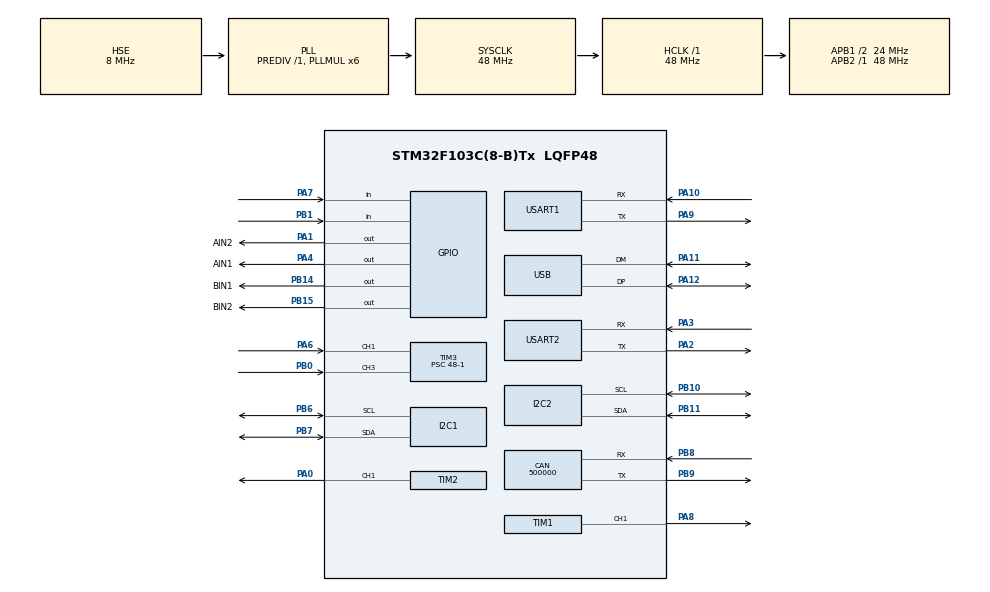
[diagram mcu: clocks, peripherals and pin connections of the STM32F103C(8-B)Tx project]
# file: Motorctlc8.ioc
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CAN.CalculateBaudRate=500000
CAN.CalculateTimeBit=2000
CAN.CalculateTimeQuantum=666.6666666666666
FREERTOS.Tasks01=IMUTask,0,128,IMUFunc,Default,NULL,Dynamic,NULL,NULL;DataTask,0,128,DataFunc,Default,NULL,Dynamic,NULL,NULL;BlanceTask,0,128,BlanceFunc,Default,NULL,Dynamic,NULL,NULL
Mcu.Family=STM32F1
Mcu.Name=STM32F103C(8-B)Tx
Mcu.Package=LQFP48
NVIC.PriorityGroup=NVIC_PRIORITYGROUP_4
NVIC.TIM3_IRQn=true\:5\:0\:false\:false\:true\:true\:true\:true\:true
NVIC.TIM4_IRQn=true\:15\:0\:false\:false\:true\:false\:false\:true\:true
NVIC.TimeBase=TIM4_IRQn
NVIC.TimeBaseIP=TIM4
NVIC.USB_LP_CAN1_RX0_IRQn=true\:5\:0\:false\:false\:true\:true\:false\:true\:true
PA0-WKUP.Signal=S_TIM2_CH1_ETR
PA1.GPIO_Label=AIN2
PA1.Signal=GPIO_Output
PA10.Mode=Asynchronous
PA10.Signal=USART1_RX
PA11.Mode=Device
PA11.Signal=USB_DM
PA12.Mode=Device
PA12.Signal=USB_DP
PA13.Mode=Serial_Wire
PA13.Signal=SYS_JTMS-SWDIO
PA14.Mode=Serial_Wire
PA14.Signal=SYS_JTCK-SWCLK
PA2.Mode=Asynchronous
PA2.Signal=USART2_TX
PA3.Mode=Asynchronous
PA3.Signal=USART2_RX
PA4.GPIO_Label=AIN1
PA4.Signal=GPIO_Output
PA6.Signal=S_TIM3_CH1
PA7.Signal=GPIO_Input
PA8.Signal=S_TIM1_CH1
PA9.Mode=Asynchronous
PA9.Signal=USART1_TX
PB0.Signal=S_TIM3_CH3
PB1.Signal=GPIO_Input
PB10.Mode=I2C
PB10.Signal=I2C2_SCL
PB11.Mode=I2C
PB11.Signal=I2C2_SDA
PB14.GPIO_Label=BIN1
PB14.Signal=GPIO_Output
PB15.GPIO_Label=BIN2
PB15.Signal=GPIO_Output
PB6.Mode=I2C
PB6.Signal=I2C1_SCL
PB7.Mode=I2C
PB7.Signal=I2C1_SDA
PB8.Mode=CAN_Activate
PB8.Signal=CAN_RX
PB9.Mode=CAN_Activate
PB9.Signal=CAN_TX
PD0-OSC_IN.Mode=HSE-External-Oscillator
PD0-OSC_IN.Signal=RCC_OSC_IN
PD1-OSC_OUT.Mode=HSE-External-Oscillator
PD1-OSC_OUT.Signal=RCC_OSC_OUT
ProjectManager.HeapSize=0x200
ProjectManager.StackSize=0x400
ProjectManager.TargetToolchain=STM32CubeIDE
RCC.AHBFreq_Value=48000000
RCC.APB1CLKDivider=RCC_HCLK_DIV2
RCC.APB1Freq_Value=24000000
RCC.APB1TimFreq_Value=48000000
RCC.APB2Freq_Value=48000000
RCC.APB2TimFreq_Value=48000000
RCC.HCLKFreq_Value=48000000
RCC.PLLMUL=RCC_PLL_MUL6
RCC.SYSCLKFreq_VALUE=48000000
RCC.SYSCLKSource=RCC_SYSCLKSOURCE_PLLCLK
RCC.USBFreq_Value=48000000
SH.S_TIM1_CH1.0=TIM1_CH1,PWM Generation1 CH1
SH.S_TIM2_CH1_ETR.0=TIM2_CH1,PWM Generation1 CH1
SH.S_TIM3_CH1.0=TIM3_CH1,Input_Capture1_from_TI1
SH.S_TIM3_CH3.0=TIM3_CH3,Input_Capture3_from_TI3
TIM1.Channel-PWM\ Generation1\ CH1=TIM_CHANNEL_1
TIM1.Period=2000
TIM1.Prescaler=48-1
TIM2.Channel-PWM\ Generation1\ CH1=TIM_CHANNEL_1
TIM2.Period=2000
TIM2.Prescaler=48-1
TIM3.AutoReloadPreload=TIM_AUTORELOAD_PRELOAD_ENABLE
TIM3.Channel-Input_Capture1_from_TI1=TIM_CHANNEL_1
TIM3.Channel-Input_Capture3_from_TI3=TIM_CHANNEL_3
TIM3.ClockDivision=TIM_CLOCKDIVISION_DIV2
TIM3.ICFilter_CH1=1
TIM3.ICFilter_CH3=1
TIM3.ICPolarity_CH1=TIM_INPUTCHANNELPOLARITY_FALLING
TIM3.ICPolarity_CH3=TIM_INPUTCHANNELPOLARITY_FALLING
TIM3.ICPrescaler-Input_Capture1_from_TI1=TIM_ICPSC_DIV2
TIM3.ICPrescaler-Input_Capture3_from_TI3=TIM_ICPSC_DIV2
TIM3.Period=50000-1
TIM3.Prescaler=48-1
USART1.VirtualMode=VM_ASYNC
USART2.VirtualMode=VM_ASYNC
USB_DEVICE.CLASS_NAME_FS=HID
USB_DEVICE.VirtualMode=Hid
USB_DEVICE.VirtualModeFS=Hid_FS
VP_FREERTOS_VS_CMSIS_V1.Mode=CMSIS_V1
VP_SYS_VS_tim4.Mode=TIM4
VP_TIM1_VS_ClockSourceINT.Mode=Internal
VP_TIM2_VS_ClockSourceINT.Mode=Internal
VP_TIM3_VS_ClockSourceINT.Mode=Internal
VP_TIM3_VS_ClockSourceITR.Mode=TriggerSource_ITR0
VP_TIM3_VS_ControllerModeTrigger.Mode=Trigger Mode
VP_USB_DEVICE_VS_USB_DEVICE_HID_FS.Mode=HID_FS
board=custom

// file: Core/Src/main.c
/* USER CODE BEGIN Header */
/**
  ******************************************************************************
  * @file           : main.c
  * @brief          : Main program body
  ******************************************************************************
  * @attention
  *
  * Copyright (c) 2025 STMicroelectronics.
  * All rights reserved.
  *
  * This software is licensed under terms that can be found in the LICENSE file
  * in the root directory of this software component.
  * If no LICENSE file comes with this software, it is provided AS-IS.
  *
  ******************************************************************************
  */
/* USER CODE END Header */
#include "main.h"
#include "cmsis_os.h"
#include "can.h"
#include "i2c.h"
#include "tim.h"
#include "usart.h"
#include "usb_device.h"
#include "gpio.h"

/* USER CODE BEGIN Includes */
#include "motor_gm37hallencoder.h"
/* USER CODE END Includes */

void SystemClock_Config(void);
void MX_FREERTOS_Init(void);

int main(void)
{

  /* MCU Configuration--------------------------------------------------------*/

  /* Reset of all peripherals, Initializes the Flash interface and the Systick. */
  HAL_Init();

  /* Configure the system clock */
  SystemClock_Config();

  /* Initialize all configured peripherals */
  MX_GPIO_Init();
  MX_CAN_Init();
  MX_I2C1_Init();
  MX_I2C2_Init();
  MX_TIM1_Init();
  MX_TIM2_Init();
  MX_USART1_UART_Init();
  MX_USART2_UART_Init();
  MX_TIM3_Init();
  /* USER CODE BEGIN 2 */
  App_Init();
  /* USER CODE END 2 */

  /* Call init function for freertos objects (in cmsis_os2.c) */
  MX_FREERTOS_Init();

  /* Start scheduler */
  osKernelStart();

  /* We should never get here as control is now taken by the scheduler */

  /* Infinite loop */
  while (1)
  {

  }
}

void SystemClock_Config(void)
{
  RCC_OscInitTypeDef RCC_OscInitStruct = {0};
  RCC_ClkInitTypeDef RCC_ClkInitStruct = {0};
  RCC_PeriphCLKInitTypeDef PeriphClkInit = {0};

  /** Initializes the RCC Oscillators according to the specified parameters
  * in the RCC_OscInitTypeDef structure.
  */
  RCC_OscInitStruct.OscillatorType = RCC_OSCILLATORTYPE_HSE;
  RCC_OscInitStruct.HSEState = RCC_HSE_ON;
  RCC_OscInitStruct.HSEPredivValue = RCC_HSE_PREDIV_DIV1;
  RCC_OscInitStruct.HSIState = RCC_HSI_ON;
  RCC_OscInitStruct.PLL.PLLState = RCC_PLL_ON;
  RCC_OscInitStruct.PLL.PLLSource = RCC_PLLSOURCE_HSE;
  RCC_OscInitStruct.PLL.PLLMUL = RCC_PLL_MUL6;
  if (HAL_RCC_OscConfig(&RCC_OscInitStruct) != HAL_OK)
  {
    Error_Handler();
  }

  /** Initializes the CPU, AHB and APB buses clocks
  */
  RCC_ClkInitStruct.ClockType = RCC_CLOCKTYPE_HCLK|RCC_CLOCKTYPE_SYSCLK
                              |RCC_CLOCKTYPE_PCLK1|RCC_CLOCKTYPE_PCLK2;
  RCC_ClkInitStruct.SYSCLKSource = RCC_SYSCLKSOURCE_PLLCLK;
  RCC_ClkInitStruct.AHBCLKDivider = RCC_SYSCLK_DIV1;
  RCC_ClkInitStruct.APB1CLKDivider = RCC_HCLK_DIV2;
  RCC_ClkInitStruct.APB2CLKDivider = RCC_HCLK_DIV1;

  if (HAL_RCC_ClockConfig(&RCC_ClkInitStruct, FLASH_LATENCY_1) != HAL_OK)
  {
    Error_Handler();
  }
  PeriphClkInit.PeriphClockSelection = RCC_PERIPHCLK_USB;
  PeriphClkInit.UsbClockSelection = RCC_USBCLKSOURCE_PLL;
  if (HAL_RCCEx_PeriphCLKConfig(&PeriphClkInit) != HAL_OK)
  {
    Error_Handler();
  }
}

void HAL_TIM_PeriodElapsedCallback(TIM_HandleTypeDef *htim)
{
  if (htim->Instance == TIM4)
  {
    HAL_IncTick();
  }
  /* USER CODE BEGIN Callback 1 */
  MotorGM37_PeriodElapsedCallback(htim);
  /* USER CODE END Callback 1 */
}

void Error_Handler(void)
{
  __disable_irq();
  while (1)
  {
  }
}

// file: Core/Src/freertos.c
/* USER CODE BEGIN Header */
/**
  ******************************************************************************
  * File Name          : freertos.c
  * Description        : Code for freertos applications
  ******************************************************************************
  * @attention
  *
  * Copyright (c) 2025 STMicroelectronics.
  * All rights reserved.
  *
  * This software is licensed under terms that can be found in the LICENSE file
  * in the root directory of this software component.
  * If no LICENSE file comes with this software, it is provided AS-IS.
  *
  ******************************************************************************
  */
/* USER CODE END Header */

#include "FreeRTOS.h"
#include "task.h"
#include "main.h"
#include "cmsis_os.h"

osThreadId IMUTaskHandle;
osThreadId DataTaskHandle;
osThreadId BlanceTaskHandle;

void IMUFunc(void const * argument);
void DataFunc(void const * argument);
void BlanceFunc(void const * argument);

extern void MX_USB_DEVICE_Init(void);
void MX_FREERTOS_Init(void); /* (MISRA C 2004 rule 8.1) */

/* GetIdleTaskMemory prototype (linked to static allocation support) */
void vApplicationGetIdleTaskMemory( StaticTask_t **ppxIdleTaskTCBBuffer, StackType_t **ppxIdleTaskStackBuffer, uint32_t *pulIdleTaskStackSize );

/* USER CODE BEGIN GET_IDLE_TASK_MEMORY */
static StaticTask_t xIdleTaskTCBBuffer;
static StackType_t xIdleStack[configMINIMAL_STACK_SIZE];

void vApplicationGetIdleTaskMemory( StaticTask_t **ppxIdleTaskTCBBuffer, StackType_t **ppxIdleTaskStackBuffer, uint32_t *pulIdleTaskStackSize )
{
  *ppxIdleTaskTCBBuffer = &xIdleTaskTCBBuffer;
  *ppxIdleTaskStackBuffer = &xIdleStack[0];
  *pulIdleTaskStackSize = configMINIMAL_STACK_SIZE;
  /* place for user code */
}
/* USER CODE END GET_IDLE_TASK_MEMORY */

void MX_FREERTOS_Init(void) {

  /* Create the thread(s) */
  /* definition and creation of IMUTask */
  osThreadDef(IMUTask, IMUFunc, osPriorityNormal, 0, 128);
  IMUTaskHandle = osThreadCreate(osThread(IMUTask), NULL);

  /* definition and creation of DataTask */
  osThreadDef(DataTask, DataFunc, osPriorityNormal, 0, 128);
  DataTaskHandle = osThreadCreate(osThread(DataTask), NULL);

  /* definition and creation of BlanceTask */
  osThreadDef(BlanceTask, BlanceFunc, osPriorityNormal, 0, 128);
  BlanceTaskHandle = osThreadCreate(osThread(BlanceTask), NULL);

}

void IMUFunc(void const * argument)
{
  /* init code for USB_DEVICE */
  MX_USB_DEVICE_Init();
  for(;;)
  {
    osDelay(1);
  }
}

void DataFunc(void const * argument)
{
  for(;;)
  {
    osDelay(1);
  }
}

void BlanceFunc(void const * argument)
{
  for(;;)
  {
    osDelay(1);
  }
}
